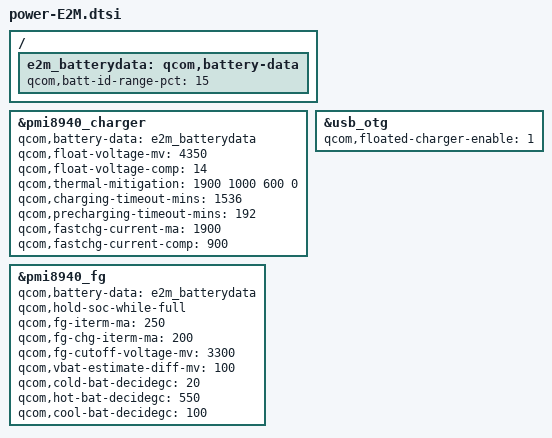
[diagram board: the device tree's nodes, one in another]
/{
	e2m_batterydata: qcom,battery-data {
		qcom,batt-id-range-pct = <15>;
		#include "components/power/batterydata-E2M_HE338cos_4100mah.dtsi"
		#include "components/power/batterydata-E2M_HE341lishen_4000mAh.dtsi"
	};
};

&pmi8940_charger {
	qcom,battery-data = <&e2m_batterydata>;
	qcom,float-voltage-mv = <4350>;
	qcom,float-voltage-comp = <14>;
	qcom,thermal-mitigation = <1900 1000 600 0>;
	qcom,charging-timeout-mins = <1536>;
	qcom,precharging-timeout-mins = <192>;
	qcom,fastchg-current-ma = <1900>;
	qcom,fastchg-current-comp = <900>;
};

&pmi8940_fg {
	qcom,battery-data = <&e2m_batterydata>;
	qcom,hold-soc-while-full;
	qcom,fg-iterm-ma = <250>;
	qcom,fg-chg-iterm-ma = <200>;
	qcom,fg-cutoff-voltage-mv = <3300>;
	qcom,vbat-estimate-diff-mv = <100>;
	qcom,cold-bat-decidegc = <20>;
	qcom,hot-bat-decidegc = <550>;
	qcom,cool-bat-decidegc = <100>;
	//qcom,warm-bat-decidegc = <450>;
};

&usb_otg {
	qcom,floated-charger-enable = <1>;
};

